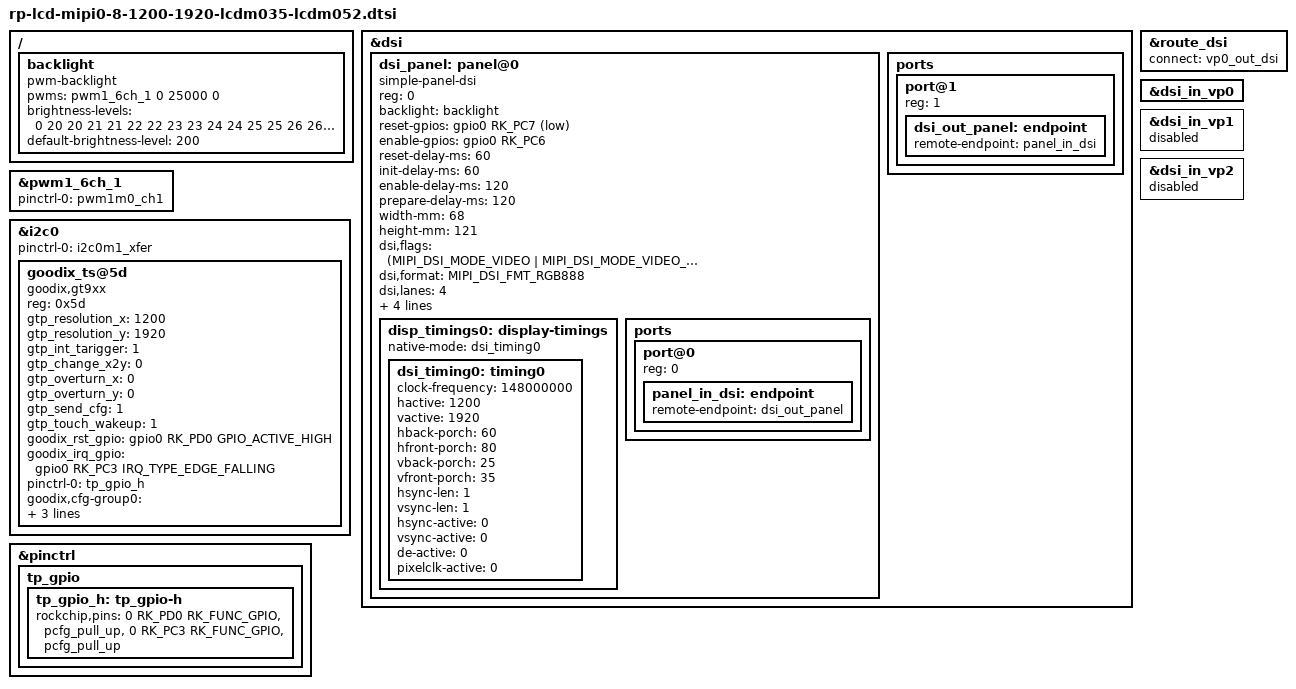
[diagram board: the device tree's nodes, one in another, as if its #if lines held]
/{
    backlight: backlight {
        compatible = "pwm-backlight";
        pwms = <&pwm1_6ch_1 0 25000 0>;
        brightness-levels = <
              0  20  20  21  21  22  22  23
             23  24  24  25  25  26  26  27
             27  28  28  29  29  30  30  31
             31  32  32  33  33  34  34  35
             35  36  36  37  37  38  38  39
             40  41  42  43  44  45  46  47
             48  49  50  51  52  53  54  55
             56  57  58  59  60  61  62  63
             64  65  66  67  68  69  70  71
             72  73  74  75  76  77  78  79
             80  81  82  83  84  85  86  87
             88  89  90  91  92  93  94  95
             96  97  98  99 100 101 102 103
            104 105 106 107 108 109 110 111
            112 113 114 115 116 117 118 119
            120 121 122 123 124 125 126 127
            128 129 130 131 132 133 134 135
            136 137 138 139 140 141 142 143
            144 145 146 147 148 149 150 151
            152 153 154 155 156 157 158 159
            160 161 162 163 164 165 166 167
            168 169 170 171 172 173 174 175
            176 177 178 179 180 181 182 183
            184 185 186 187 188 189 190 191
            192 193 194 195 196 197 198 199
            200 201 202 203 204 205 206 207
            208 209 210 211 212 213 214 215
            216 217 218 219 220 221 222 223
            224 225 226 227 228 229 230 231
            232 233 234 235 236 237 238 239
            240 241 242 243 244 245 246 247
            248 249 250 251 252 253 254 255
        >;
        default-brightness-level = <200>;
    };
};

&dsi {
    status = "okay";
   // rockchip,lane-rate = <1200>;
    dsi_panel: panel@0 {
        status = "okay";
        compatible = "simple-panel-dsi";
        reg = <0>;
        backlight = <&backlight>;
        
        reset-gpios = <&gpio0 RK_PC7 GPIO_ACTIVE_LOW>;
        enable-gpios = <&gpio0 RK_PC6 GPIO_ACTIVE_HIGH>;
       
	reset-delay-ms = <60>;
                init-delay-ms = <60>;
                enable-delay-ms = <120>;
                prepare-delay-ms = <120>;

 
        width-mm = <68>;
        height-mm = <121>;
        dsi,flags = <(MIPI_DSI_MODE_VIDEO | MIPI_DSI_MODE_VIDEO_BURST |
                  MIPI_DSI_MODE_LPM | MIPI_DSI_MODE_NO_EOT_PACKET)>;
        dsi,format = <MIPI_DSI_FMT_RGB888>;
        dsi,lanes  = <4>;
        panel-init-sequence = [
            05 78 01 11
            05 00 01 29
        ];

        panel-exit-sequence = [
            05 00 01 28
            05 00 01 10
        ];

        disp_timings0: display-timings {
            native-mode = <&dsi_timing0>;
            dsi_timing0: timing0 {
		clock-frequency = <148000000>;
                                hactive = <1200>;
                                vactive = <1920>;
                                hback-porch = <60>;
                                hfront-porch = <80>;
                                vback-porch = <25>;
                                vfront-porch = <35>;
                                hsync-len = <1>;
                                vsync-len = <1>;
                                hsync-active = <0>;
                                vsync-active = <0>;
                                de-active = <0>;
                                pixelclk-active = <0>;
            };
        };

        ports {
            #address-cells = <1>;
            #size-cells = <0>;

            port@0 {
                reg = <0>;
                panel_in_dsi: endpoint {
                    remote-endpoint = <&dsi_out_panel>;
                };
            };
        };
    };

    ports {
        #address-cells = <1>;
        #size-cells = <0>;

        port@1 {
            reg = <1>;
            dsi_out_panel: endpoint {
                remote-endpoint = <&panel_in_dsi>;
            };
        };
    };

};


#if defined RP_RK3576S || defined DR4_RK3576X || defined PRO_RK3576X

&route_dsi {
    status = "okay";
    connect = <&vp0_out_dsi>;
};

&pwm1_6ch_1 {
    status = "okay";
    pinctrl-0 = <&pwm1m0_ch1>;
};

&dsi_in_vp0 {
    status = "okay";
};

&dsi_in_vp1 {
    status = "disabled";
};

&dsi_in_vp2 {
    status = "disabled";
};


#else  //rk3576

&route_dsi {
    status = "okay";
};

&pwm1_6ch_1 {
    status = "okay";
    pinctrl-0 = <&pwm1m0_ch1>;
};

//default to hdmi
&dsi_in_vp0 {
    status = "disabled";
};

&dsi_in_vp1 {
    status = "okay";
};

&dsi_in_vp2 {
    status = "disabled";
};

&dsi_in_vopl {
    status = "okay";
};

#endif

//TP
&i2c0 {
    status = "okay";
    pinctrl-names = "default";
    pinctrl-0 = <&i2c0m1_xfer>;
    goodix_ts@5d {
        compatible = "goodix,gt9xx";
        reg = <0x5d>;
        gtp_resolution_x = <1200>;
        gtp_resolution_y = <1920>;
        gtp_int_tarigger = <1>;
        gtp_change_x2y = <0>;
        gtp_overturn_x = <0>;
        gtp_overturn_y = <0>;
        gtp_send_cfg = <1>;
        gtp_touch_wakeup = <1>;
        goodix_rst_gpio = <&gpio0 RK_PD0 GPIO_ACTIVE_HIGH>;
        goodix_irq_gpio = <&gpio0 RK_PC3 IRQ_TYPE_EDGE_FALLING>;
	pinctrl-names = "default";
        pinctrl-0 = <&tp_gpio_h>;

	goodix,cfg-group0 = [
                5E B0 04 80 07 05 05 00 01 0F 28 05 
                50 32 03 05 00 00 00 00 00 00 00 00
                00 00 00 8C 2C 0E 52 54 31 0D 00 00
                01 80 04 1C 00 00 00 00 00 03 64 32
                00 00 00 52 66 94 C5 02 07 00 00 04
                83 53 00 82 57 00 80 5B 00 7F 5F 00
                7E 63 00 7E 00 00 00 00 00 00 00 00
                00 00 00 00 00 00 00 00 00 00 00 00
                00 00 00 00 00 00 00 00 00 00 00 00
                00 00 00 00 1C 1A 18 16 14 12 10 0E
                0C 0A 08 06 04 02 FF FF FF FF FF FF
                FF FF FF FF FF FF FF FF FF FF 00 02
                04 06 08 0A 0C 0F 10 12 13 14 28 26
                24 22 21 20 1F 1E 1D 1C 18 16 FF FF
                FF FF FF FF FF FF FF FF FF FF FF FF
                FF FF FF FF 22 01
        ];
	
	goodix,cfg-group2 = [
        00 20 03 00 05 0A 05 00 01 08 28
        05 50 32 03 05 00 00 00 00 00 00
        00 00 00 00 00 8C 2C 0E 17 15 31
        0D 00 00 01 BA 03 1D 00 00 00 00
        00 03 64 32 00 00 00 0F 41 94 C5
        02 07 00 00 04 99 11 00 77 17 00
        5F 1F 00 4C 2A 00 41 38 00 41 00
        00 00 00 00 00 00 00 00 00 00 00
        00 00 00 00 00 00 00 00 00 00 00
        00 00 00 00 00 00 00 00 00 00 00
        00 00 1C 1A 18 16 14 12 10 0E 0C
        0A 08 06 04 02 00 00 00 00 00 00
        00 00 00 00 00 00 00 00 00 00 28
        26 24 22 21 20 1F 1E 1D 1C 18 16
        00 02 04 06 08 0A 0C 0F 10 12 13
        14 FF FF 00 00 00 00 00 00 00 00
        00 00 00 00 00 00 00 00 FE 01
        ];

    };
};

&pinctrl {
    tp_gpio {
		tp_gpio_h: tp_gpio-h {
			rockchip,pins = <0 RK_PD0 RK_FUNC_GPIO &pcfg_pull_up>,
                            <0 RK_PC3 RK_FUNC_GPIO &pcfg_pull_up>;
		};
	};
};


